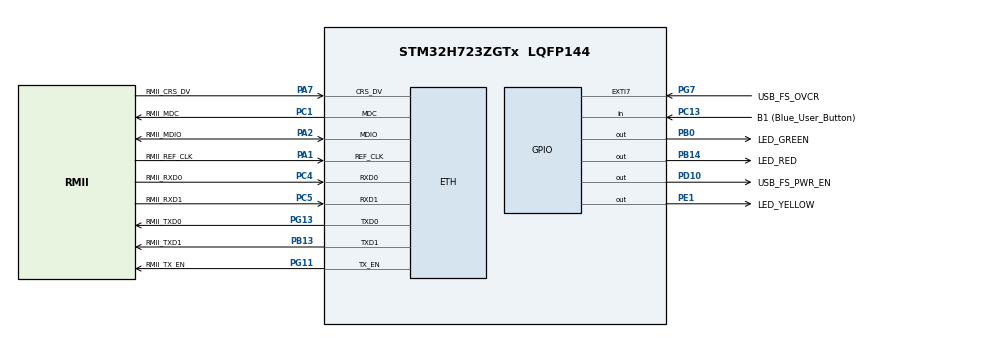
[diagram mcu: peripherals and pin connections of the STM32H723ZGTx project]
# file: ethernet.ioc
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CORTEX_M7.AccessPermission-Cortex_Memory_Protection_Unit_Region0_Settings=MPU_REGION_NO_ACCESS
CORTEX_M7.AccessPermission-Cortex_Memory_Protection_Unit_Region1_Settings=MPU_REGION_FULL_ACCESS
CORTEX_M7.AccessPermission-Cortex_Memory_Protection_Unit_Region2_Settings=MPU_REGION_FULL_ACCESS
CORTEX_M7.BaseAddress-Cortex_Memory_Protection_Unit_Region0_Settings=0x00
CORTEX_M7.BaseAddress-Cortex_Memory_Protection_Unit_Region1_Settings=0x30000000
CORTEX_M7.BaseAddress-Cortex_Memory_Protection_Unit_Region2_Settings=0x30004000
CORTEX_M7.CPU_DCache=Enabled
CORTEX_M7.CPU_ICache=Enabled
CORTEX_M7.DisableExec-Cortex_Memory_Protection_Unit_Region0_Settings=MPU_INSTRUCTION_ACCESS_DISABLE
CORTEX_M7.DisableExec-Cortex_Memory_Protection_Unit_Region1_Settings=MPU_INSTRUCTION_ACCESS_ENABLE
CORTEX_M7.Enable-Cortex_Memory_Protection_Unit_Region0_Settings=MPU_REGION_ENABLE
CORTEX_M7.Enable-Cortex_Memory_Protection_Unit_Region1_Settings=MPU_REGION_ENABLE
CORTEX_M7.Enable-Cortex_Memory_Protection_Unit_Region2_Settings=MPU_REGION_ENABLE
CORTEX_M7.IsBufferable-Cortex_Memory_Protection_Unit_Region1_Settings=MPU_ACCESS_BUFFERABLE
CORTEX_M7.IsCacheable-Cortex_Memory_Protection_Unit_Region0_Settings=MPU_ACCESS_NOT_CACHEABLE
CORTEX_M7.IsShareable-Cortex_Memory_Protection_Unit_Region0_Settings=MPU_ACCESS_SHAREABLE
CORTEX_M7.IsShareable-Cortex_Memory_Protection_Unit_Region2_Settings=MPU_ACCESS_SHAREABLE
CORTEX_M7.MPU_Control=MPU_PRIVILEGED_DEFAULT
CORTEX_M7.Size-Cortex_Memory_Protection_Unit_Region0_Settings=MPU_REGION_SIZE_4GB
CORTEX_M7.Size-Cortex_Memory_Protection_Unit_Region1_Settings=MPU_REGION_SIZE_1KB
CORTEX_M7.Size-Cortex_Memory_Protection_Unit_Region2_Settings=MPU_REGION_SIZE_16KB
CORTEX_M7.SubRegionDisable-Cortex_Memory_Protection_Unit_Region0_Settings=0x87
CORTEX_M7.TypeExtField-Cortex_Memory_Protection_Unit_Region0_Settings=MPU_TEX_LEVEL0
CORTEX_M7.TypeExtField-Cortex_Memory_Protection_Unit_Region2_Settings=MPU_TEX_LEVEL1
ETH.MediaInterface=HAL_ETH_RMII_MODE
ETH.RxBuffLen=1524
ETH.TxDescAddress=0x30000200
LWIP.BSP.number=1
LWIP.GATEWAY_ADDRESS=192.168.000.001
LWIP.IP_ADDRESS=192.168.000.123
LWIP.LWIP_DHCP=0
LWIP.LWIP_RAM_HEAP_POINTER=0x30004000
LWIP.MEM_SIZE=10*1024
LWIP.NETMASK_ADDRESS=255.255.255.000
LWIP.Version=v2.1.2_Cube
LWIP0.BSP.STBoard=false
LWIP0.BSP.api=BSP_COMPONENT_DRIVER
LWIP0.BSP.component=LAN8742
LWIP0.BSP.instance=LAN8742
LWIP0.BSP.name=Driver_PHY
LWIP0.BSP.semaphore=S_LAN8742
LWIP0.BSP.solution=LAN8742
Mcu.Family=STM32H7
Mcu.Name=STM32H723ZGTx
Mcu.Package=LQFP144
NVIC.PriorityGroup=NVIC_PRIORITYGROUP_4
PA1.GPIO_Label=RMII_REF_CLK
PA1.GPIO_Speed=GPIO_SPEED_FREQ_VERY_HIGH
PA1.Mode=RMII
PA1.Signal=ETH_REF_CLK
PA10.GPIO_Label=USB_FS_ID
PA10.Signal=USB_OTG_HS_ID
PA13(JTMS/SWDIO).GPIO_Label=SWDIO
PA13(JTMS/SWDIO).Signal=DEBUG_JTMS-SWDIO
PA14(JTCK/SWCLK).GPIO_Label=SWCLK
PA14(JTCK/SWCLK).Signal=DEBUG_JTCK-SWCLK
PA2.GPIO_Label=RMII_MDIO
PA2.GPIO_Speed=GPIO_SPEED_FREQ_VERY_HIGH
PA2.Mode=RMII
PA2.Signal=ETH_MDIO
PA7.GPIO_Label=RMII_CRS_DV
PA7.GPIO_Speed=GPIO_SPEED_FREQ_VERY_HIGH
PA7.Mode=RMII
PA7.Signal=ETH_CRS_DV
PA9.GPIO_Label=USB_FS_VBUS
PA9.Signal=USB_OTG_HS_VBUS
PB0.GPIO_Label=LED_GREEN
PB0.Signal=GPIO_Output
PB13.GPIO_Label=RMII_TXD1
PB13.GPIO_Speed=GPIO_SPEED_FREQ_VERY_HIGH
PB13.Mode=RMII
PB13.Signal=ETH_TXD1
PB14.GPIO_Label=LED_RED
PB14.Signal=GPIO_Output
PB3(JTDO/TRACESWO).GPIO_Label=SWO
PB3(JTDO/TRACESWO).Signal=DEBUG_JTDO-SWO
PC1.GPIO_Label=RMII_MDC
PC1.GPIO_Speed=GPIO_SPEED_FREQ_VERY_HIGH
PC1.Mode=RMII
PC1.Signal=ETH_MDC
PC13.GPIO_Label=B1 (Blue_User_Button)
PC13.Signal=GPIO_Input
PC14-OSC32_IN.Signal=RCC_OSC32_IN
PC15-OSC32_OUT.Signal=RCC_OSC32_OUT
PC4.GPIO_Label=RMII_RXD0
PC4.GPIO_Speed=GPIO_SPEED_FREQ_VERY_HIGH
PC4.Mode=RMII
PC4.Signal=ETH_RXD0
PC5.GPIO_Label=RMII_RXD1
PC5.GPIO_Speed=GPIO_SPEED_FREQ_VERY_HIGH
PC5.Mode=RMII
PC5.Signal=ETH_RXD1
PD10.GPIO_Label=USB_FS_PWR_EN
PD10.Signal=GPIO_Output
PD8.GPIO_Label=STLK_VCP_RX
PD8.Signal=USART3_TX
PD9.GPIO_Label=STLK_VCP_TX
PD9.Signal=USART3_RX
PE1.GPIO_Label=LED_YELLOW
PE1.Signal=GPIO_Output
PG11.GPIO_Label=RMII_TX_EN
PG11.GPIO_Speed=GPIO_SPEED_FREQ_VERY_HIGH
PG11.Mode=RMII
PG11.Signal=ETH_TX_EN
PG13.GPIO_Label=RMII_TXD0
PG13.GPIO_Speed=GPIO_SPEED_FREQ_VERY_HIGH
PG13.Mode=RMII
PG13.Signal=ETH_TXD0
PG7.GPIO_Label=USB_FS_OVCR
PG7.Signal=GPXTI7
PH0-OSC_IN.GPIO_Label=MCO
PH0-OSC_IN.Mode=HSE-External-Oscillator
PH0-OSC_IN.Signal=RCC_OSC_IN
PH1-OSC_OUT.Mode=HSE-External-Oscillator
PH1-OSC_OUT.Signal=RCC_OSC_OUT
ProjectManager.HeapSize=0x200
ProjectManager.StackSize=0x400
ProjectManager.TargetToolchain=STM32CubeIDE
RCC.ADCFreq_Value=76000000
RCC.APB1Freq_Value=137500000
RCC.APB2Freq_Value=137500000
RCC.APB3Freq_Value=137500000
RCC.APB4Freq_Value=137500000
RCC.CortexFreq_Value=550000000
RCC.D1PPRE=RCC_APB3_DIV2
RCC.D2PPRE1=RCC_APB1_DIV2
RCC.D2PPRE2=RCC_APB2_DIV2
RCC.D3PPRE=RCC_APB4_DIV2
RCC.DIVM1=1
RCC.DIVM2=1
RCC.DIVN1=68
RCC.DIVN2=19
RCC.DIVP1=1
RCC.DIVQ1=4
RCC.HCLKFreq_Value=275000000
RCC.HPRE=RCC_HCLK_DIV2
RCC.HSE_VALUE=8000000
RCC.PLLFRACN=6144
RCC.PLLSourceVirtual=RCC_PLLSOURCE_HSE
RCC.SYSCLKFreq_VALUE=550000000
RCC.SYSCLKSource=RCC_SYSCLKSOURCE_PLLCLK
RCC.USBCLockSelection=RCC_USBCLKSOURCE_HSI48
RCC.USBFreq_Value=48000000
VP_LWIP_VS_Enabled.Mode=Enabled
board=NUCLEO-H723ZG

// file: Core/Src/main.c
/* USER CODE BEGIN Header */
/**
  ******************************************************************************
  * @file           : main.c
  * @brief          : Main program body
  ******************************************************************************
  * @attention
  *
  * Copyright (c) 2022 STMicroelectronics.
  * All rights reserved.
  *
  * This software is licensed under terms that can be found in the LICENSE file
  * in the root directory of this software component.
  * If no LICENSE file comes with this software, it is provided AS-IS.
  *
  ******************************************************************************
  */
/* USER CODE END Header */
#include "main.h"
#include "lwip.h"

/* USER CODE BEGIN Includes */
#include "lwip/opt.h"
#include "lwip/init.h"
#include "netif/etharp.h"
#include "lwip/netif.h"
#include "lwip/timeouts.h"
#if LWIP_DHCP
#include "lwip/dhcp.h"
#endif
#include "ethernetif.h"

/* USER CODE END Includes */

void SystemClock_Config(void);
static void MPU_Config(void);
static void MX_GPIO_Init(void);

/* USER CODE BEGIN 0 */
extern struct netif gnetif;
//struct netif gnetif;

/* USER CODE END 0 */

int main(void)
{

  /* MPU Configuration--------------------------------------------------------*/
  MPU_Config();

  /* Enable I-Cache---------------------------------------------------------*/
  SCB_EnableICache();

  /* Enable D-Cache---------------------------------------------------------*/
  SCB_EnableDCache();

  /* MCU Configuration--------------------------------------------------------*/

  /* Reset of all peripherals, Initializes the Flash interface and the Systick. */
  HAL_Init();

  /* Configure the system clock */
  SystemClock_Config();

  /* Initialize all configured peripherals */
  MX_GPIO_Init();
  MX_LWIP_Init();

  /* Infinite loop */
  while (1)
  {

    /* USER CODE BEGIN 3 */
	ethernetif_input(&gnetif);

	/* Handle timeouts */
	sys_check_timeouts();

  }
  /* USER CODE END 3 */
}

void SystemClock_Config(void)
{
  RCC_OscInitTypeDef RCC_OscInitStruct = {0};
  RCC_ClkInitTypeDef RCC_ClkInitStruct = {0};

  /** Supply configuration update enable
  */
  HAL_PWREx_ConfigSupply(PWR_LDO_SUPPLY);

  /** Configure the main internal regulator output voltage
  */
  __HAL_PWR_VOLTAGESCALING_CONFIG(PWR_REGULATOR_VOLTAGE_SCALE0);

  while(!__HAL_PWR_GET_FLAG(PWR_FLAG_VOSRDY)) {}

  /** Initializes the RCC Oscillators according to the specified parameters
  * in the RCC_OscInitTypeDef structure.
  */
  RCC_OscInitStruct.OscillatorType = RCC_OSCILLATORTYPE_HSE;
  RCC_OscInitStruct.HSEState = RCC_HSE_ON;
  RCC_OscInitStruct.PLL.PLLState = RCC_PLL_ON;
  RCC_OscInitStruct.PLL.PLLSource = RCC_PLLSOURCE_HSE;
  RCC_OscInitStruct.PLL.PLLM = 1;
  RCC_OscInitStruct.PLL.PLLN = 68;
  RCC_OscInitStruct.PLL.PLLP = 1;
  RCC_OscInitStruct.PLL.PLLQ = 4;
  RCC_OscInitStruct.PLL.PLLR = 2;
  RCC_OscInitStruct.PLL.PLLRGE = RCC_PLL1VCIRANGE_3;
  RCC_OscInitStruct.PLL.PLLVCOSEL = RCC_PLL1VCOWIDE;
  RCC_OscInitStruct.PLL.PLLFRACN = 6144;
  if (HAL_RCC_OscConfig(&RCC_OscInitStruct) != HAL_OK)
  {
    Error_Handler();
  }

  /** Initializes the CPU, AHB and APB buses clocks
  */
  RCC_ClkInitStruct.ClockType = RCC_CLOCKTYPE_HCLK|RCC_CLOCKTYPE_SYSCLK
                              |RCC_CLOCKTYPE_PCLK1|RCC_CLOCKTYPE_PCLK2
                              |RCC_CLOCKTYPE_D3PCLK1|RCC_CLOCKTYPE_D1PCLK1;
  RCC_ClkInitStruct.SYSCLKSource = RCC_SYSCLKSOURCE_PLLCLK;
  RCC_ClkInitStruct.SYSCLKDivider = RCC_SYSCLK_DIV1;
  RCC_ClkInitStruct.AHBCLKDivider = RCC_HCLK_DIV2;
  RCC_ClkInitStruct.APB3CLKDivider = RCC_APB3_DIV2;
  RCC_ClkInitStruct.APB1CLKDivider = RCC_APB1_DIV2;
  RCC_ClkInitStruct.APB2CLKDivider = RCC_APB2_DIV2;
  RCC_ClkInitStruct.APB4CLKDivider = RCC_APB4_DIV2;

  if (HAL_RCC_ClockConfig(&RCC_ClkInitStruct, FLASH_LATENCY_3) != HAL_OK)
  {
    Error_Handler();
  }
}

static void MX_GPIO_Init(void)
{
  GPIO_InitTypeDef GPIO_InitStruct = {0};

  /* GPIO Ports Clock Enable */
  __HAL_RCC_GPIOC_CLK_ENABLE();
  __HAL_RCC_GPIOH_CLK_ENABLE();
  __HAL_RCC_GPIOA_CLK_ENABLE();
  __HAL_RCC_GPIOB_CLK_ENABLE();
  __HAL_RCC_GPIOD_CLK_ENABLE();
  __HAL_RCC_GPIOG_CLK_ENABLE();
  __HAL_RCC_GPIOE_CLK_ENABLE();

  /*Configure GPIO pin Output Level */
  HAL_GPIO_WritePin(GPIOB, LED_GREEN_Pin|LED_RED_Pin, GPIO_PIN_RESET);

  /*Configure GPIO pin Output Level */
  HAL_GPIO_WritePin(USB_FS_PWR_EN_GPIO_Port, USB_FS_PWR_EN_Pin, GPIO_PIN_RESET);

  /*Configure GPIO pin Output Level */
  HAL_GPIO_WritePin(LED_YELLOW_GPIO_Port, LED_YELLOW_Pin, GPIO_PIN_RESET);

  /*Configure GPIO pin : B1_Pin */
  GPIO_InitStruct.Pin = B1_Pin;
  GPIO_InitStruct.Mode = GPIO_MODE_INPUT;
  GPIO_InitStruct.Pull = GPIO_NOPULL;
  HAL_GPIO_Init(B1_GPIO_Port, &GPIO_InitStruct);

  /*Configure GPIO pins : LED_GREEN_Pin LED_RED_Pin */
  GPIO_InitStruct.Pin = LED_GREEN_Pin|LED_RED_Pin;
  GPIO_InitStruct.Mode = GPIO_MODE_OUTPUT_PP;
  GPIO_InitStruct.Pull = GPIO_NOPULL;
  GPIO_InitStruct.Speed = GPIO_SPEED_FREQ_LOW;
  HAL_GPIO_Init(GPIOB, &GPIO_InitStruct);

  /*Configure GPIO pins : STLK_VCP_RX_Pin STLK_VCP_TX_Pin */
  GPIO_InitStruct.Pin = STLK_VCP_RX_Pin|STLK_VCP_TX_Pin;
  GPIO_InitStruct.Mode = GPIO_MODE_AF_PP;
  GPIO_InitStruct.Pull = GPIO_NOPULL;
  GPIO_InitStruct.Speed = GPIO_SPEED_FREQ_LOW;
  GPIO_InitStruct.Alternate = GPIO_AF7_USART3;
  HAL_GPIO_Init(GPIOD, &GPIO_InitStruct);

  /*Configure GPIO pin : USB_FS_PWR_EN_Pin */
  GPIO_InitStruct.Pin = USB_FS_PWR_EN_Pin;
  GPIO_InitStruct.Mode = GPIO_MODE_OUTPUT_PP;
  GPIO_InitStruct.Pull = GPIO_NOPULL;
  GPIO_InitStruct.Speed = GPIO_SPEED_FREQ_LOW;
  HAL_GPIO_Init(USB_FS_PWR_EN_GPIO_Port, &GPIO_InitStruct);

  /*Configure GPIO pin : USB_FS_OVCR_Pin */
  GPIO_InitStruct.Pin = USB_FS_OVCR_Pin;
  GPIO_InitStruct.Mode = GPIO_MODE_IT_RISING;
  GPIO_InitStruct.Pull = GPIO_NOPULL;
  HAL_GPIO_Init(USB_FS_OVCR_GPIO_Port, &GPIO_InitStruct);

  /*Configure GPIO pin : USB_FS_ID_Pin */
  GPIO_InitStruct.Pin = USB_FS_ID_Pin;
  GPIO_InitStruct.Mode = GPIO_MODE_AF_PP;
  GPIO_InitStruct.Pull = GPIO_NOPULL;
  GPIO_InitStruct.Speed = GPIO_SPEED_FREQ_LOW;
  GPIO_InitStruct.Alternate = GPIO_AF10_OTG1_HS;
  HAL_GPIO_Init(USB_FS_ID_GPIO_Port, &GPIO_InitStruct);

  /*Configure GPIO pin : LED_YELLOW_Pin */
  GPIO_InitStruct.Pin = LED_YELLOW_Pin;
  GPIO_InitStruct.Mode = GPIO_MODE_OUTPUT_PP;
  GPIO_InitStruct.Pull = GPIO_NOPULL;
  GPIO_InitStruct.Speed = GPIO_SPEED_FREQ_LOW;
  HAL_GPIO_Init(LED_YELLOW_GPIO_Port, &GPIO_InitStruct);

}

/* MPU Configuration */

void MPU_Config(void)
{
  MPU_Region_InitTypeDef MPU_InitStruct = {0};

  /* Disables the MPU */
  HAL_MPU_Disable();

  /** Initializes and configures the Region and the memory to be protected
  */
  MPU_InitStruct.Enable = MPU_REGION_ENABLE;
  MPU_InitStruct.Number = MPU_REGION_NUMBER0;
  MPU_InitStruct.BaseAddress = 0x00;
  MPU_InitStruct.Size = MPU_REGION_SIZE_4GB;
  MPU_InitStruct.SubRegionDisable = 0x87;
  MPU_InitStruct.TypeExtField = MPU_TEX_LEVEL0;
  MPU_InitStruct.AccessPermission = MPU_REGION_NO_ACCESS;
  MPU_InitStruct.DisableExec = MPU_INSTRUCTION_ACCESS_DISABLE;
  MPU_InitStruct.IsShareable = MPU_ACCESS_SHAREABLE;
  MPU_InitStruct.IsCacheable = MPU_ACCESS_NOT_CACHEABLE;
  MPU_InitStruct.IsBufferable = MPU_ACCESS_NOT_BUFFERABLE;

  HAL_MPU_ConfigRegion(&MPU_InitStruct);

  /** Initializes and configures the Region and the memory to be protected
  */
  MPU_InitStruct.Number = MPU_REGION_NUMBER1;
  MPU_InitStruct.BaseAddress = 0x30000000;
  MPU_InitStruct.Size = MPU_REGION_SIZE_1KB;
  MPU_InitStruct.SubRegionDisable = 0x0;
  MPU_InitStruct.AccessPermission = MPU_REGION_FULL_ACCESS;
  MPU_InitStruct.DisableExec = MPU_INSTRUCTION_ACCESS_ENABLE;
  MPU_InitStruct.IsShareable = MPU_ACCESS_NOT_SHAREABLE;
  MPU_InitStruct.IsBufferable = MPU_ACCESS_BUFFERABLE;

  HAL_MPU_ConfigRegion(&MPU_InitStruct);

  /** Initializes and configures the Region and the memory to be protected
  */
  MPU_InitStruct.Number = MPU_REGION_NUMBER2;
  MPU_InitStruct.BaseAddress = 0x30004000;
  MPU_InitStruct.Size = MPU_REGION_SIZE_16KB;
  MPU_InitStruct.TypeExtField = MPU_TEX_LEVEL1;
  MPU_InitStruct.IsShareable = MPU_ACCESS_SHAREABLE;
  MPU_InitStruct.IsBufferable = MPU_ACCESS_NOT_BUFFERABLE;

  HAL_MPU_ConfigRegion(&MPU_InitStruct);
  /* Enables the MPU */
  HAL_MPU_Enable(MPU_PRIVILEGED_DEFAULT);

}

void Error_Handler(void)
{
  __disable_irq();
  while (1)
  {
  }
}
